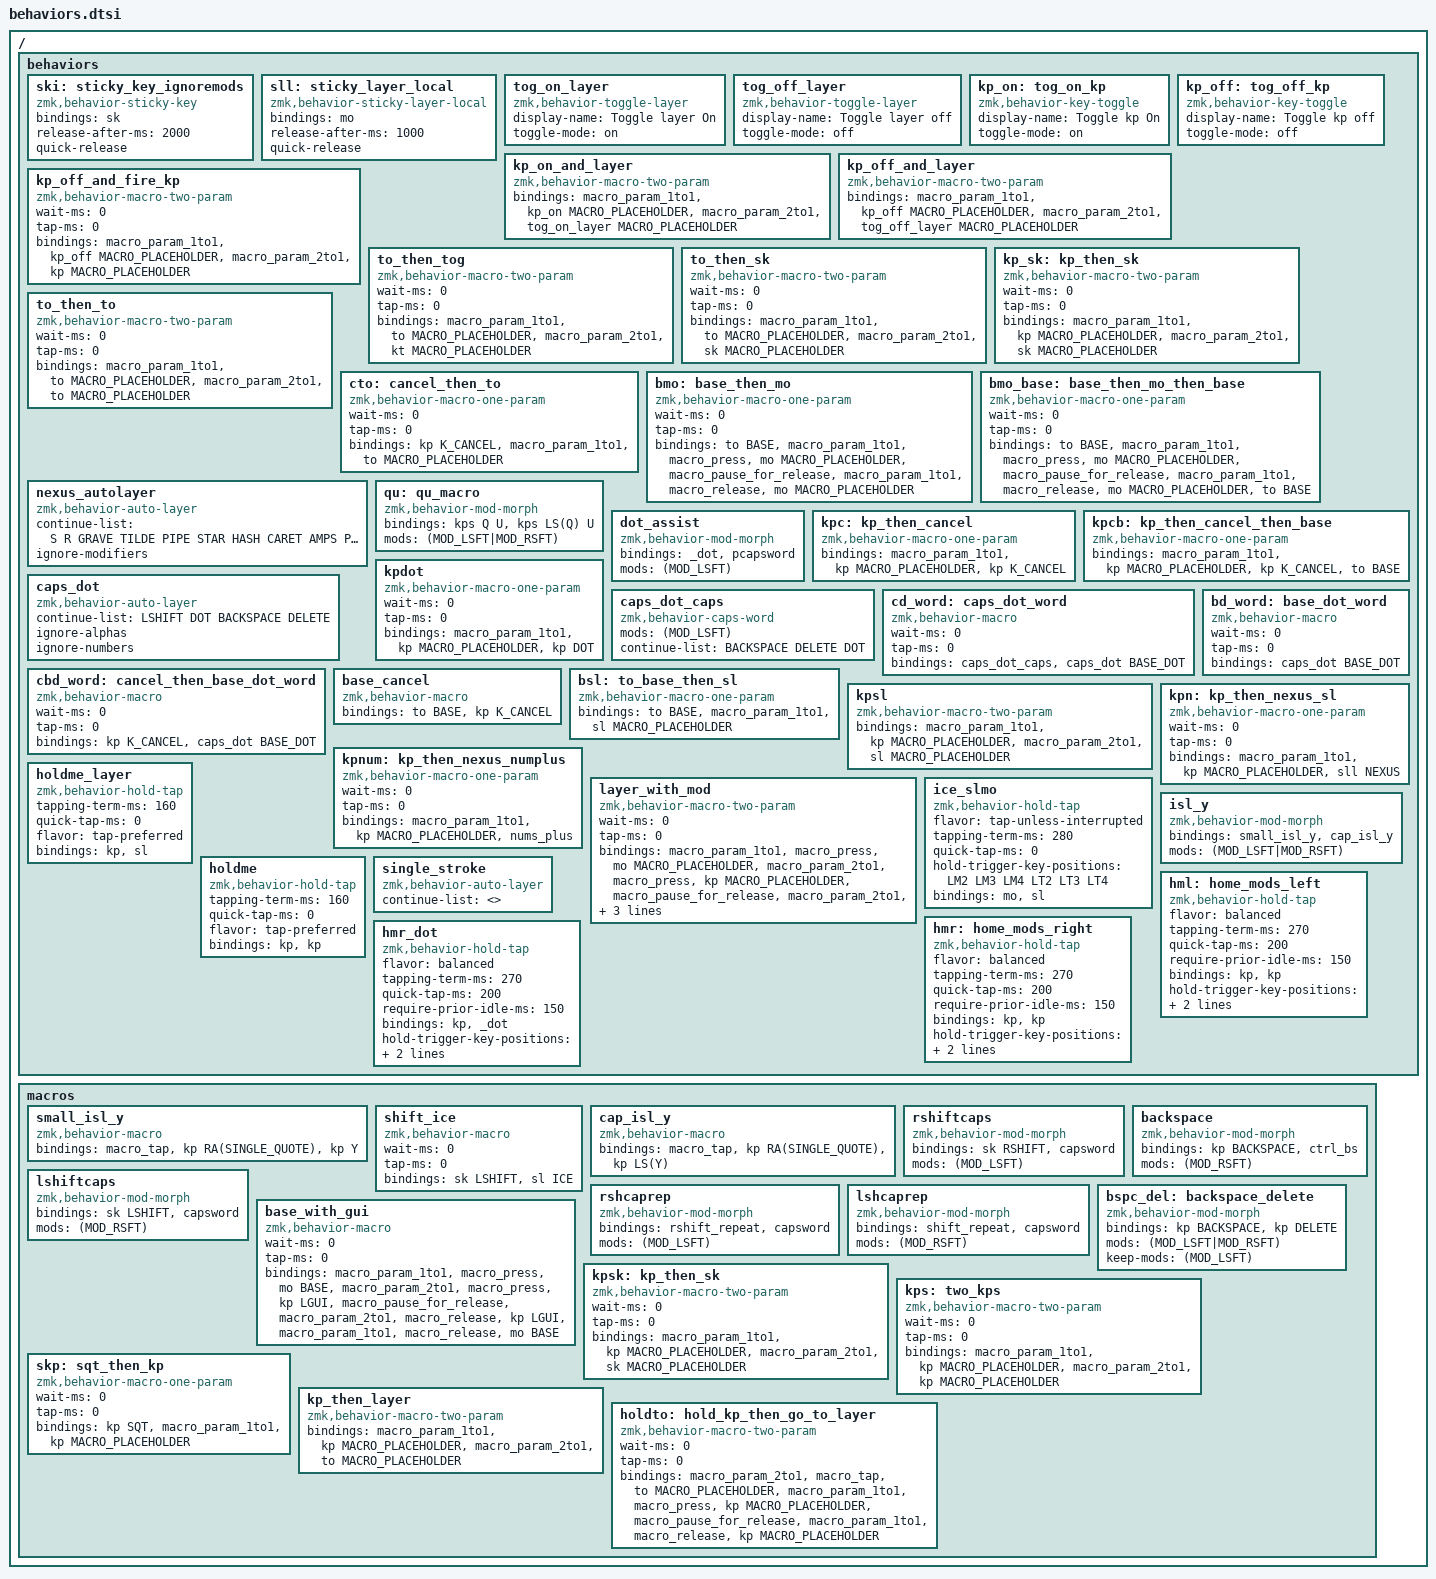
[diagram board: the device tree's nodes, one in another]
#include "navigation.dtsi"
#include "numword.dtsi"
#include "capsword.dtsi"
#include "mouse.dtsi"
#include "adaptive_keys.dtsi"
#include "mod_locks.dtsi"
#include "strict_kps.dtsi"
#include "convenience_mod_morphs.dtsi"
#include "scroller.dtsi"
#include "tristates.dtsi"
#include "pgupdn.dtsi"

#define stay kp CLEAR_AGAIN

/ {
	behaviors {
		
			ski: sticky_key_ignoremods {
				compatible = "zmk,behavior-sticky-key";
				#binding-cells = <1>;
				bindings = <&sk>;
				release-after-ms = <2000>;
	      quick-release;
				/delete-property/ ignore-modifiers;
			};

			sll: sticky_layer_local {
				compatible = "zmk,behavior-sticky-layer-local";
				#binding-cells = <1>;
				bindings = <&mo>;
				release-after-ms = <1000>;
	      quick-release;
			};
    
    // eeeh virkaði ekki
		/* sln: sl_norelease { */
		/* 	compatible = "zmk,behavior-sticky-key"; */
		/* 	#binding-cells = <1>; */
		/* 	bindings = <&sl>; */
		/*     release-after-ms = <5000>; */
		/*     /delete-property/ quick-release; */
		/* }; */


		tog_on_layer: tog_on_layer {
			compatible = "zmk,behavior-toggle-layer";
			#binding-cells = <1>;
			display-name = "Toggle layer On";
			toggle-mode = "on";
		};
		
		tog_off_layer: tog_off_layer {
			compatible = "zmk,behavior-toggle-layer";
			#binding-cells = <1>;
			display-name = "Toggle layer off";
			toggle-mode = "off";
		};
		
		kp_on: tog_on_kp {
			compatible = "zmk,behavior-key-toggle";
			#binding-cells = <1>;
			display-name = "Toggle kp On";
			toggle-mode = "on";
		};
		
		kp_off: tog_off_kp {
			compatible = "zmk,behavior-key-toggle";
			#binding-cells = <1>;
			display-name = "Toggle kp off";
			toggle-mode = "off";
		};
		
		
		kp_on_and_layer: kp_on_and_layer {
			compatible = "zmk,behavior-macro-two-param";
			#binding-cells = <2>;
			bindings =  <&macro_param_1to1>, <&kp_on MACRO_PLACEHOLDER>,
			<&macro_param_2to1>, <&tog_on_layer MACRO_PLACEHOLDER>;
		};
		
		kp_off_and_layer: kp_off_and_layer {
			compatible = "zmk,behavior-macro-two-param";
			#binding-cells = <2>;
			bindings =  <&macro_param_1to1>, <&kp_off MACRO_PLACEHOLDER>,
			<&macro_param_2to1>, <&tog_off_layer MACRO_PLACEHOLDER>;
		};
    
		kp_off_and_fire_kp: kp_off_and_fire_kp {
			compatible = "zmk,behavior-macro-two-param";
			#binding-cells = <2>;
			wait-ms = <0>;
			tap-ms = <0>;
			bindings =  <&macro_param_1to1>, <&kp_off MACRO_PLACEHOLDER>,
			<&macro_param_2to1>, <&kp MACRO_PLACEHOLDER>;
		};
		
		

		to_then_tog: to_then_tog {
			compatible = "zmk,behavior-macro-two-param";
			#binding-cells = <2>;
			wait-ms = <0>;
			tap-ms = <0>;
			bindings =  <&macro_param_1to1>, <&to MACRO_PLACEHOLDER>,
			<&macro_param_2to1>, <&kt MACRO_PLACEHOLDER>;
		};
		
		to_then_sk: to_then_sk {
			compatible = "zmk,behavior-macro-two-param";
			#binding-cells = <2>;
			wait-ms = <0>;
			tap-ms = <0>;
			bindings =  <&macro_param_1to1>, <&to MACRO_PLACEHOLDER>,
			<&macro_param_2to1>, <&sk MACRO_PLACEHOLDER>;
		};

		kp_sk: kp_then_sk {
			compatible = "zmk,behavior-macro-two-param";
			#binding-cells = <2>;
			wait-ms = <0>;
			tap-ms = <0>;
			bindings =  <&macro_param_1to1>, <&kp MACRO_PLACEHOLDER>,
			<&macro_param_2to1>, <&sk MACRO_PLACEHOLDER>;
		};

		to_then_to: to_then_to {
			compatible = "zmk,behavior-macro-two-param";
			#binding-cells = <2>;
			wait-ms = <0>;
			tap-ms = <0>;
			bindings =  <&macro_param_1to1>, <&to MACRO_PLACEHOLDER>,
			<&macro_param_2to1>, <&to MACRO_PLACEHOLDER>;
		};
		
		cto: cancel_then_to {
			compatible = "zmk,behavior-macro-one-param";
			#binding-cells = <1>;
			wait-ms = <0>;
			tap-ms = <0>;
			bindings = <&kp K_CANCEL>, <&macro_param_1to1>, <&to MACRO_PLACEHOLDER>;
		};

		bmo: base_then_mo {
			compatible = "zmk,behavior-macro-one-param";
			#binding-cells = <1>;
			wait-ms = <0>;
			tap-ms = <0>;
			bindings
			= <&to BASE>
			, <&macro_param_1to1>
			, <&macro_press &mo MACRO_PLACEHOLDER>
			, <&macro_pause_for_release>
			, <&macro_param_1to1>
			, <&macro_release &mo MACRO_PLACEHOLDER>
			;
		};

		bmo_base: base_then_mo_then_base {
			compatible = "zmk,behavior-macro-one-param";
			#binding-cells = <1>;
			wait-ms = <0>;
			tap-ms = <0>;
			/* Hold the target layer while pressed, then force a clean return to BASE. */
			bindings
			= <&to BASE>
			, <&macro_param_1to1>
			, <&macro_press &mo MACRO_PLACEHOLDER>
			, <&macro_pause_for_release>
			, <&macro_param_1to1>
			, <&macro_release &mo MACRO_PLACEHOLDER>
			, <&to BASE>
			;
		};

		nexus_autolayer: nexus_autolayer {
			compatible = "zmk,behavior-auto-layer";
			#binding-cells = <1>;
			continue-list = <S R GRAVE TILDE PIPE STAR HASH CARET AMPS PRCNT LPAR RPAR LBRC RBRC LBKT RBKT DQT BSLH FSLH QMARK COMMA DOT SQT EXCL SEMI COLON BACKSPACE UNDER>;
			ignore-modifiers;
		};

		/* nexus_auto: nexus_auto { */
		/* 	compatible = "zmk,behavior-macro"; */
		/* 	#binding-cells = <0>; */
		/* 	wait-ms = <0>; */
		/* 	tap-ms = <0>; */
		/* 	bindings = <&kp K_CANCEL>, <&nexus_autolayer NEXUS>; */
		/* }; */

    /* nexus_auto: nexus_auto { */
    /*   compatible = "zmk,behavior-macro"; */
    /*   #binding-cells = <0>; */
    /*   wait-ms = <0>; */
    /*   tap-ms = <0>; */
    /*   bindings */
    /*   = <&macro_tap &nexus_autolayer NEXUS> */
    /*   , <&macro_pause_for_release> */
    /*   , <&macro_tap &nexus_autolayer NEXUS>; */
    /* }; */

    /* nexus_auto: nexus_auto { */
    /*     compatible = "zmk,behavior-macro"; */
    /*     #binding-cells = <0>; */
    /*     wait-ms = <0>; */
    /*     tap-ms = <10>; */
    /*     bindings = */
    /*           <&macro_tap &to BASE> */
    /*         , <&macro_pause_for_release> */
    /*         , <&macro_tap &to BASE> */
    /*         , <&macro_tap &nexus_autolayer NEXUS>; */
    /* }; */

		qu: qu_macro {
			compatible = "zmk,behavior-mod-morph";
			#binding-cells = <0>;
			bindings = <&kps Q U>, <&kps LS(Q) U>;
			mods = <(MOD_LSFT|MOD_RSFT)>;
		};

		dot_assist: dot_assist { 
			compatible = "zmk,behavior-mod-morph";
			#binding-cells = <0>;
			bindings = <&_dot>, <&pcapsword>;
			mods = <(MOD_LSFT)>;
		};
		
		kpc: kp_then_cancel {
			compatible = "zmk,behavior-macro-one-param";
			#binding-cells = <1>;
			bindings = <&macro_param_1to1>, <&kp MACRO_PLACEHOLDER>, <&kp K_CANCEL>;
		};
		
		kpcb: kp_then_cancel_then_base {
			compatible = "zmk,behavior-macro-one-param";
			#binding-cells = <1>;
			bindings = <&macro_param_1to1>, <&kp MACRO_PLACEHOLDER>, <&kp K_CANCEL>, <&to BASE>;
		};

		kpdot: kpdot {
			compatible = "zmk,behavior-macro-one-param";
			#binding-cells = <1>;
			wait-ms = <0>;
			tap-ms = <0>;
			bindings = <&macro_param_1to1>, <&kp MACRO_PLACEHOLDER>, <&kp DOT>;
		};

		caps_dot: caps_dot {
			compatible = "zmk,behavior-auto-layer";
			#binding-cells = <1>;
			continue-list = <LSHIFT DOT BACKSPACE DELETE>;
			ignore-alphas;
			ignore-numbers;
		};

		caps_dot_caps: caps_dot_caps {
			compatible = "zmk,behavior-caps-word";
			#binding-cells = <0>;
			mods = <(MOD_LSFT)>;
      // Default: underscore, backspace, delete, alphanumerics
      // verður að taka aftur fram undrescore, backspace og delete
      // en alphanumerics koma sjálfkrafa
			continue-list = <
        BACKSPACE DELETE 
        DOT 
      >;
		};

    cd_word: caps_dot_word {
			compatible = "zmk,behavior-macro";
			#binding-cells = <0>;
			wait-ms = <0>;
			tap-ms = <0>;
			bindings = <&caps_dot_caps &caps_dot BASE_DOT>;
		};

    bd_word: base_dot_word {
			compatible = "zmk,behavior-macro";
			#binding-cells = <0>;
			wait-ms = <0>;
			tap-ms = <0>;
			bindings = <&caps_dot BASE_DOT>;
		};

    cbd_word: cancel_then_base_dot_word {
			compatible = "zmk,behavior-macro";
			#binding-cells = <0>;
			wait-ms = <0>;
			tap-ms = <0>;
			bindings = <&kp K_CANCEL &caps_dot BASE_DOT>;
		};

		base_cancel: base_cancel {
			compatible = "zmk,behavior-macro";
			#binding-cells = <0>;
			bindings = <&to BASE &kp K_CANCEL>;
		};

		bsl: to_base_then_sl {
			compatible = "zmk,behavior-macro-one-param";
			#binding-cells = <1>;
			bindings = <&to BASE>, <&macro_param_1to1>, <&sl MACRO_PLACEHOLDER>;
		};

		kpsl: kpsl {
			compatible = "zmk,behavior-macro-two-param";
			#binding-cells = <2>;
			bindings = <&macro_param_1to1>, <&kp MACRO_PLACEHOLDER>, <&macro_param_2to1>, <&sl MACRO_PLACEHOLDER>;
		};

	    kpn: kp_then_nexus_sl {
				compatible = "zmk,behavior-macro-one-param";
				#binding-cells = <1>;
				wait-ms = <0>;
				tap-ms = <0>;
				bindings = <&macro_param_1to1>, <&kp MACRO_PLACEHOLDER>, <&sll NEXUS>;
	      /* bindings =  */
	      /*        <&to BASE>            // Ensure clean slate */
	      /*        ,<&macro_param_1to1> */
	      /*        , <&kp MACRO_PLACEHOLDER> */
	              /* , <&macro_wait_time 10> // Let the old layers die */
      /*        , <&sl NEXUS>;          // Add the new layer */
    };

    kpnum: kp_then_nexus_numplus {
			compatible = "zmk,behavior-macro-one-param";
			#binding-cells = <1>;
			wait-ms = <0>;
			tap-ms = <0>;
			bindings = <&macro_param_1to1>, <&kp MACRO_PLACEHOLDER>, <&nums_plus>;
    };

		
		layer_with_mod: layer_with_mod {
			compatible = "zmk,behavior-macro-two-param";
			wait-ms = <0>;
			tap-ms = <0>;
			#binding-cells = <2>;
			bindings
			= <&macro_param_1to1>
			, <&macro_press &mo MACRO_PLACEHOLDER>
			, <&macro_param_2to1>
			, <&macro_press &kp MACRO_PLACEHOLDER>
			, <&macro_pause_for_release>
			, <&macro_param_2to1>
			, <&macro_release &kp MACRO_PLACEHOLDER>
			, <&macro_param_1to1>
			, <&macro_release &mo MACRO_PLACEHOLDER>
			;
		};
		
		
		/* movegui_word: movegui_word { */
			/* 	compatible = "zmk,behavior-tri-state"; */
			/* 	#binding-cells = <0>; */
			/* 	bindings = <&to_then_tog NAVIGATION LGUI>, <&none>, <&to_then_tog BASE LGUI>; */
			/* 	ignored-key-positions = < */
			/* 	POS_LH_C5R2 POS_LH_C4R2 POS_LH_C3R2 POS_LH_C2R2 POS_LH_C1R2     POS_RH_C1R2 POS_RH_C2R2 POS_RH_C3R2 POS_RH_C4R2 POS_RH_C5R2 */
			/* 	POS_LH_C4R4 POS_LH_C3R4 POS_LH_C2R4                 POS_RH_C1R4 POS_RH_C2R4 POS_RH_C3R4 POS_RH_C4R4 */
			/* 	POS_LH_T1 */
			/* 	>; */
			/* 	ignored-layers = <NAVIGATION>; */
			/* 	timeout-ms = <4000>; */
		/* }; */

			holdme_layer: holdme_layer {
				compatible = "zmk,behavior-hold-tap";
				#binding-cells = <2>;
				tapping-term-ms = <160>;
				quick-tap-ms = <0>;
				flavor = "tap-preferred";
				bindings = <&kp>, <&sl>;
			};

			ice_slmo: ice_slmo {
				compatible = "zmk,behavior-hold-tap";
				#binding-cells = <2>;
				// Tap => one-shot ICE.
				// Hold => only when another key is pressed before timeout, and only for vowel positions.
				flavor = "tap-unless-interrupted";
				tapping-term-ms = <280>;
				quick-tap-ms = <0>;
				hold-trigger-key-positions = <LM2 LM3 LM4 LT2 LT3 LT4>;
				bindings = <&mo>, <&sl>;
			};
	};
	
	macros {
		small_isl_y: small_isl_y {
			compatible = "zmk,behavior-macro";
			#binding-cells = <0>;
			bindings = <&macro_tap &kp RA(SINGLE_QUOTE) &kp Y>;
		};


		shift_ice: shift_ice {
			compatible = "zmk,behavior-macro";
			#binding-cells = <0>;
			wait-ms = <0>;
			tap-ms = <0>;
			bindings = <&sk LSHIFT &sl ICE>;
		};
		
		cap_isl_y: cap_isl_y {
			compatible = "zmk,behavior-macro";
			#binding-cells = <0>;
			bindings = <&macro_tap &kp RA(SINGLE_QUOTE) &kp LS(Y)>;
		};
		
		rshiftcaps: rshiftcaps {
			compatible = "zmk,behavior-mod-morph";
			#binding-cells = <0>;
			bindings = <&sk RSHIFT>, <&capsword>;
			mods = <(MOD_LSFT)>;
		};

		backspace: backspace {
			compatible = "zmk,behavior-mod-morph";
			#binding-cells = <0>;
			bindings = <&kp BACKSPACE>, <&ctrl_bs>;
			mods = <(MOD_RSFT)>;
		};


		lshiftcaps: lshiftcaps {
			compatible = "zmk,behavior-mod-morph";
			#binding-cells = <0>;
			bindings = <&sk LSHIFT>, <&capsword>;
			mods = <(MOD_RSFT)>;
		};


		rshcaprep: rshcaprep {
			compatible = "zmk,behavior-mod-morph";
			#binding-cells = <0>;
			bindings = <&rshift_repeat>, <&capsword>;
			mods = <(MOD_LSFT)>;
		};

		lshcaprep: lshcaprep {
			compatible = "zmk,behavior-mod-morph";
			#binding-cells = <0>;
			bindings = <&shift_repeat>, <&capsword>;
			mods = <(MOD_RSFT)>;
		};

		bspc_del: backspace_delete {
			compatible = "zmk,behavior-mod-morph";
			#binding-cells = <0>;
			bindings = <&kp BACKSPACE>, <&kp DELETE>;
			mods = <(MOD_LSFT|MOD_RSFT)>;
			keep-mods = <(MOD_LSFT)>;
		};
		
		base_with_gui: base_with_gui {
			compatible = "zmk,behavior-macro";
			#binding-cells = <0>;
			wait-ms = <0>;
			tap-ms = <0>;
			bindings
			= <&macro_param_1to1>
			, <&macro_press &mo BASE>
			, <&macro_param_2to1>
			, <&macro_press &kp LGUI>
			, <&macro_pause_for_release>
			, <&macro_param_2to1>
			, <&macro_release &kp LGUI>
			, <&macro_param_1to1>
			, <&macro_release &mo BASE>
			;
		};
		
		#define UNICODE(name, ...) \
		ZMK_MACRO(name, \
		wait-ms = <1>; \
		tap-ms = <1>; \
		bindings = __VA_ARGS__; \
		)
		
		UNICODE(degsign, /* ° */
		<&kp LC(LS(U))>,
		<&kp B &kp N0 &kp ENTER>
		)
		
		UNICODE(polish_l,
		<&kp LC(LS(U))>,
		<&kp N1 &kp N4 &kp N2 &kp ENTER>
		)
		UNICODE(polish_capital_l,
		<&kp LC(LS(U))>,
		<&kp N1 &kp N4 &kp N1 &kp ENTER>
		)
		
		kpsk: kp_then_sk {
			compatible = "zmk,behavior-macro-two-param";
			#binding-cells = <2>;
			/* wait-ms = <40>; */
			/* tap-ms = <40>; */
			wait-ms = <0>;
			tap-ms = <0>;
			bindings =  <&macro_param_1to1>, <&kp MACRO_PLACEHOLDER>,
			<&macro_param_2to1>, <&sk MACRO_PLACEHOLDER>;
		};
		
		kps: two_kps {
			compatible = "zmk,behavior-macro-two-param";
			#binding-cells = <2>;
			/* wait-ms = <40>; */
			/* tap-ms = <40>; */
			wait-ms = <0>;
			tap-ms = <0>;
			bindings =  <&macro_param_1to1>, <&kp MACRO_PLACEHOLDER>,
			<&macro_param_2to1>, <&kp MACRO_PLACEHOLDER>;
		};

		skp: sqt_then_kp {
			compatible = "zmk,behavior-macro-one-param";
			#binding-cells = <1>;
			wait-ms = <0>;
			tap-ms = <0>;
			bindings =  <&kp SQT>, <&macro_param_1to1>, <&kp MACRO_PLACEHOLDER>;
		};
		
		
		kp_then_layer: kp_then_layer {
			compatible = "zmk,behavior-macro-two-param";
			#binding-cells = <2>;
			bindings
			= <&macro_param_1to1>, <&kp MACRO_PLACEHOLDER>,
			<&macro_param_2to1>, <&to MACRO_PLACEHOLDER>;
		};

    holdto: hold_kp_then_go_to_layer {
        compatible = "zmk,behavior-macro-two-param";
        wait-ms = <0>;
        tap-ms = <0>;
        #binding-cells = <2>;
        bindings
            = 
            <&macro_param_2to1>
            , <&macro_tap &to MACRO_PLACEHOLDER>
            , <&macro_param_1to1>
            , <&macro_press &kp MACRO_PLACEHOLDER>
            , <&macro_pause_for_release>
            , <&macro_param_1to1>
            , <&macro_release &kp MACRO_PLACEHOLDER>
            ;
    };


  };
      
      
	behaviors {
		isl_y: isl_y {
			compatible = "zmk,behavior-mod-morph";
			#binding-cells = <0>;
			bindings = <&small_isl_y>, <&cap_isl_y>;
			mods = <(MOD_LSFT|MOD_RSFT)>;
		};
		
			holdme: holdme {
				compatible = "zmk,behavior-hold-tap";
				#binding-cells = <2>;
				tapping-term-ms = <160>;
				quick-tap-ms = <0>;
				flavor = "tap-preferred";
				bindings = <&kp>, <&kp>;
			};
		
		single_stroke: single_stroke {
			compatible = "zmk,behavior-auto-layer";
			#binding-cells = <1>;
			continue-list = <>;
		};


		/* sqt_nex: sqt_nex { */
		/* 	compatible = "zmk,behavior-macro"; */
		/* 	#binding-cells = <0>; */
		/* 	wait-ms = <0>; */
		/* 	tap-ms = <0>; */
		/* 	bindings = <&kp SQT>, <&sl NEXUS_OVER>; */
		/* }; */
		
		/* sk_sh_o: sticky_shift_with_overlay { */
			/* 	compatible = "zmk,behavior-macro"; */
			/* 	#binding-cells = <0>; */
			/* 	bindings = < */
			/* 	&sk LSHIFT */
			/* 	&single_stroke KCAN_OVER */
			/* 	>; */
		/* }; */
		
		/* sksh: sksh { */
			/* 	compatible = "zmk,behavior-hold-tap"; */
			/* 	#binding-cells = <2>; */
			/* 	flavor = "balanced"; */
			/* 	tapping-term-ms = <200>; */
			/* 	bindings = <&kp>, <&sk_sh_o>; */
		/* }; */
		
		// |------------------------|------------------------|
		// | LEFT_HAND_KEYS         |        RIGHT_HAND_KEYS |
		// |                        |                        |
		// |  0  1  2  3  4         |          5  6  7  8  9 |
		// | 10 11 12 13 14 15      |      16 17 18 19 20 21 |
		// | 22 23 24 25 26 27      |      28 29 30 31 32 33 |
		// | 34 35 36 37 38 39      |      40 41 42 43 44 45 |
		// | 46 47 48 49 50 51      |      58 59 60 61 62 63 |
		// | 64 65 66 67 68         |         75 76 77 78 79 |
		// |                69 52   |   57 74                |
		// |                 70 53  |  56 73                 |
		// |                  71 54 | 55 72                  |
		// |------------------------|------------------------|
		//

		/*   left */
		/* 0  1  2  3  4       \ */
		/* 10 11 12 13 14 15    \ */
		/* 22 23 24 25 26 27    \ */
		/* 34 35 36 37 38 39    \ */
		/* 46 47 48 49 50 51    \ */
		/* 64 65 66 67 68 */
		/*   right */
		/* 5  6  7  8  9 \ */
		/* 16 17 18 19 20 21 \ */
		/* 28 29 30 31 32 33 \ */
		/* 40 41 42 43 44 45 \ */
		/* 58 59 60 61 62 63 \ */
		/* 75 76 77 78 79 */
		/*   thumbs, 69 er space og 74 er R */
		/* 69 52       57 74                \ */
		/*  70 53     56 73                 \ */
		/*   71 54   55 72 */

		#define LEFT_HAND_KEYS      \
		0  1  2  3  4       \
		10 11 12 13 14 15    \
		22 23 24 25 26 27    \
		34 35 36 37 38 39    \
		46 47 48 49 50 51    \
		64 65 66 67 68
		#define RIGHT_HAND_KEYS     \
		5  6  7  8  9 \
		16 17 18 19 20 21 \
		28 29 30 31 32 33 \
		40 41 42 43 44 45 \
		58 59 60 61 62 63 \
		75 76 77 78 79
		#define THUMB_KEYS          \
		69 52       57 74                \
		70 53     56 73                 \
		71 54   55 72
		
		
		
		hml: home_mods_left {
			compatible = "zmk,behavior-hold-tap";
			#binding-cells = <2>;
			flavor = "balanced";
			// út af require-prior-idle-ms og flavor = balanced
			// kemur tapping-term-ms ekki mikið við sögu, 
			// hér eru samt tvær aðstæður þar sem það verður relevant:
			// ef þú vilt gera mod+bokstaf á sömu hlið, 
			// td halda inni hrm fyrir LGUI og svo yta á bókstaf á sömu hlið,
			// getur þá bara haldið inni aðeins lengur
			// sama ef vilt halda inni LGUI og ýta á músartakka
			// (með actual mús)
			// annað: ef vilt actually ýta á mod sem takka, 
			// td ýta á """windows""" takkann til að fá upp menu
			// þarft þá að halda honum inni tapping-term-ms lengi
			tapping-term-ms = <270>;
			quick-tap-ms = <200>;
			require-prior-idle-ms = <150>;
			bindings = <&kp>, <&kp>;
			hold-trigger-key-positions = <RIGHT_HAND_KEYS THUMB_KEYS>;
			// hold-trigger-on-release lætur hold-trigger-key-positions
			// resolveast eftir release, ekki press, sem er nauðsynlegt
			// fyrir að combinea mods, td gui + ctrl eða whatever
			hold-trigger-on-release;
		};
		
		hmr: home_mods_right {
			compatible = "zmk,behavior-hold-tap";
			#binding-cells = <2>;
			flavor = "balanced";
			tapping-term-ms = <270>;
			quick-tap-ms = <200>;
			require-prior-idle-ms = <150>;
			bindings = <&kp>, <&kp>;
			hold-trigger-key-positions = <LEFT_HAND_KEYS THUMB_KEYS>;
			hold-trigger-on-release;
		};
		
		hmr_dot: hmr_dot {
			compatible = "zmk,behavior-hold-tap";
			#binding-cells = <2>;
			flavor = "balanced";
			tapping-term-ms = <270>;
			quick-tap-ms = <200>;
			require-prior-idle-ms = <150>;
			bindings = <&kp>, <&_dot>;
			hold-trigger-key-positions = <LEFT_HAND_KEYS THUMB_KEYS>;
			hold-trigger-on-release;
		};

	};
	
};
